VERSION ""

NS_ :

BS_:
BU_: RaspPi1 RaspPi2

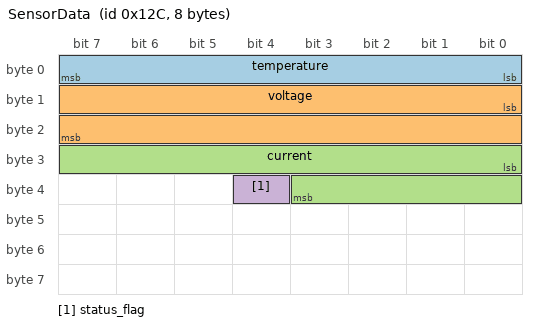
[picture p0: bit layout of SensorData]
BO_ 300 SensorData: 8 RaspPi1
 SG_ temperature : 0|8@1+ (1,0) [0|255] "°C" RaspPi2
 SG_ voltage     : 8|16@1+ (0.1,0) [0|6553.5] "V" RaspPi2
 SG_ current     : 24|12@1+ (0.01,0) [0|40.95] "A" RaspPi2
 SG_ status_flag : 36|1@1+ (1,0) [0|1] "" RaspPi2

BO_ 301 AckMessage: 1 RaspPi2
 SG_ ack : 0|1@1+ (1,0) [0|1] "" RaspPi1
